AUTOSAR XML (schema 00048)
package /ComponentTypes
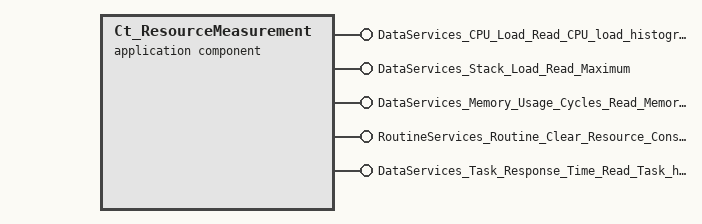
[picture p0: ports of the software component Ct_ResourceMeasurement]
  application sw component type Ct_ResourceMeasurement
    5 x provide port:
      DataServices_CPU_Load_Read_CPU_load_histograms: provided-interface=DataServices_CPU_Load_Read_CPU_load_histograms
        provided-com-specs:
          operation=ConditionCheckRead, queue-length=1
          operation=ReadDataLength, queue-length=1
          operation=ReadData, queue-length=1
      DataServices_Stack_Load_Read_Maximum: provided-interface=DataServices_Stack_Load_Read_Maximum
        provided-com-specs:
          operation=ConditionCheckRead, queue-length=1
          operation=ReadDataLength, queue-length=1
          operation=ReadData, queue-length=1
      DataServices_Memory_Usage_Cycles_Read_Memory_Usage_Cycles: provided-interface=DataServices_Memory_Usage_Cycles_Read_Memory_Usage_Cycles
        provided-com-specs:
          operation=ConditionCheckRead, queue-length=1
          operation=ReadDataLength, queue-length=1
          operation=ReadData, queue-length=1
      RoutineServices_Routine_Clear_Resource_Consumption_Data_Start: server-com-spec{operation=Start, queue-length=1}, provided-interface=RoutineServices_Routine_Clear_Resource_Consumption_Data_Start
      DataServices_Task_Response_Time_Read_Task_histograms: provided-interface=DataServices_Task_Response_Time_Read_Task_histograms
        provided-com-specs:
          operation=ConditionCheckRead, queue-length=1
          operation=ReadDataLength, queue-length=1
          operation=ReadData, queue-length=1
    behavior Ct_ResourceMeasurement_InternalBehavior
      13 x operation invoked event:
        OIT_Runnable_DataServices_CPU_Load_Read_CPU_load_histograms_ConditionCheckRead: start-on-event=DataServices_CPU_Load_Read_CPU_load_histograms_ConditionCheckRead, operation=DataServices_CPU_Load_Read_CPU_load_histograms.ConditionCheckRead
        OIT_Runnable_DataServices_CPU_Load_Read_CPU_load_histograms_ReadData: start-on-event=DataServices_CPU_Load_Read_CPU_load_histograms_ReadData, operation=DataServices_CPU_Load_Read_CPU_load_histograms.ReadData
        OIT_Runnable_DataServices_CPU_Load_Read_CPU_load_histograms_ReadDataLength: start-on-event=DataServices_CPU_Load_Read_CPU_load_histograms_ReadDataLength, operation=DataServices_CPU_Load_Read_CPU_load_histograms.ReadDataLength
        OIT_Runnable_DataServices_Stack_Load_Read_Maximum_ConditionCheckRead: start-on-event=DataServices_Stack_Load_Read_Maximum_ConditionCheckRead, operation=DataServices_Stack_Load_Read_Maximum.ConditionCheckRead
        OIT_Runnable_DataServices_Stack_Load_Read_Maximum_ReadData: start-on-event=DataServices_Stack_Load_Read_Maximum_ReadData, operation=DataServices_Stack_Load_Read_Maximum.ReadData
        OIT_Runnable_DataServices_Stack_Load_Read_Maximum_ReadDataLength: start-on-event=DataServices_Stack_Load_Read_Maximum_ReadDataLength, operation=DataServices_Stack_Load_Read_Maximum.ReadDataLength
        OIT_Runnable_DataServices_Memory_Usage_Cycles_Read_Memory_Usage_Cycles_ConditionCheckRead: start-on-event=DataServices_Memory_Usage_Cycles_Read_Memory_Usage_Cycles_ConditionCheckRead, operation=DataServices_Memory_Usage_Cycles_Read_Memory_Usage_Cycles.ConditionCheckRead
        OIT_Runnable_DataServices_Memory_Usage_Cycles_Read_Memory_Usage_Cycles_ReadData: start-on-event=DataServices_Memory_Usage_Cycles_Read_Memory_Usage_Cycles_ReadData, operation=DataServices_Memory_Usage_Cycles_Read_Memory_Usage_Cycles.ReadData
        OIT_Runnable_DataServices_Memory_Usage_Cycles_Read_Memory_Usage_Cycles_ReadDataLength: start-on-event=DataServices_Memory_Usage_Cycles_Read_Memory_Usage_Cycles_ReadDataLength, operation=DataServices_Memory_Usage_Cycles_Read_Memory_Usage_Cycles.ReadDataLength
        OIT_Runnable_RoutineServices_Routine_Clear_Resource_Consumption_Data_Start_Start: start-on-event=RoutineServices_Routine_Clear_Resource_Consumption_Data_Start_Start, operation=RoutineServices_Routine_Clear_Resource_Consumption_Data_Start.Start
        OIT_Runnable_DataServices_Task_Response_Time_Read_Task_histograms_ConditionCheckRead: start-on-event=DataServices_Task_Response_Time_Read_Task_histograms_ConditionCheckRead, operation=DataServices_Task_Response_Time_Read_Task_histograms.ConditionCheckRead
        OIT_Runnable_DataServices_Task_Response_Time_Read_Task_histograms_ReadData: start-on-event=DataServices_Task_Response_Time_Read_Task_histograms_ReadData, operation=DataServices_Task_Response_Time_Read_Task_histograms.ReadData
        OIT_Runnable_DataServices_Task_Response_Time_Read_Task_histograms_ReadDataLength: start-on-event=DataServices_Task_Response_Time_Read_Task_histograms_ReadDataLength, operation=DataServices_Task_Response_Time_Read_Task_histograms.ReadDataLength
      13 x runnable:
        DataServices_CPU_Load_Read_CPU_load_histograms_ConditionCheckRead
        DataServices_CPU_Load_Read_CPU_load_histograms_ReadData
        DataServices_CPU_Load_Read_CPU_load_histograms_ReadDataLength
        DataServices_Stack_Load_Read_Maximum_ConditionCheckRead
        DataServices_Stack_Load_Read_Maximum_ReadData
        DataServices_Stack_Load_Read_Maximum_ReadDataLength
        DataServices_Memory_Usage_Cycles_Read_Memory_Usage_Cycles_ConditionCheckRead
        DataServices_Memory_Usage_Cycles_Read_Memory_Usage_Cycles_ReadData
        DataServices_Memory_Usage_Cycles_Read_Memory_Usage_Cycles_ReadDataLength
        RoutineServices_Routine_Clear_Resource_Consumption_Data_Start_Start
        DataServices_Task_Response_Time_Read_Task_histograms_ConditionCheckRead
        DataServices_Task_Response_Time_Read_Task_histograms_ReadData
        DataServices_Task_Response_Time_Read_Task_histograms_ReadDataLength
  swc implementation Ct_ResourceMeasurement_Implementation: behavior=Ct_ResourceMeasurement_InternalBehavior
